AUTOSAR XML (schema 4-3-0)
package /LedCtrl
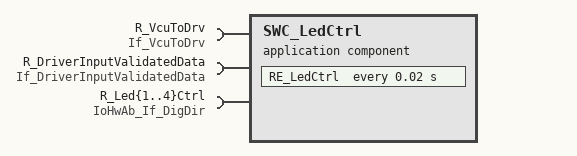
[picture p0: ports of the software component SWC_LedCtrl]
  application sw component type SWC_LedCtrl
    6 x require port:
      R_VcuToDrv: required-com-specs=[RegenLevel, RegenEnable, LimitReason], required-interface=If_VcuToDrv
      R_DriverInputValidatedData: nonqueued-receiver-com-spec=DriverInputFault, required-interface=If_DriverInputValidatedData
      R_Led{1..4}Ctrl: client-com-spec=WriteDirect, required-interface=IoHwAb_If_DigDir
    behavior InternalBehavior
      timing event TE_RE_LedCtrl: start-on-event=RE_LedCtrl, period=0.02
      runnable RE_LedCtrl: symbol=LedCtrl_func
        data-receive-point-by-arguments:
          access DRPBA_RE_LedCtrl_R_DriverInputValidatedData_DriverInputFault: accessed-variable=R_DriverInputValidatedData.DriverInputFault, scope=COMMUNICATION-INTER-ECU
          access DRPBA_RE_LedCtrl_R_VcuToDrv_RegenEnable: accessed-variable=R_VcuToDrv.RegenEnable, scope=COMMUNICATION-INTER-ECU
          access DRPBA_RE_LedCtrl_R_VcuToDrv_RegenLevel: accessed-variable=R_VcuToDrv.RegenLevel, scope=COMMUNICATION-INTER-ECU
        4 x sync call:
          SSCP_RE_LedCtrl_R_LedCtrl_WriteDirect: operation=R_Led1Ctrl.WriteDirect
          SSCP_RE_LedCtrl_R_Led{2..4}Ctrl_WriteDirect: operation=R_Led{2..4}Ctrl.WriteDirect
